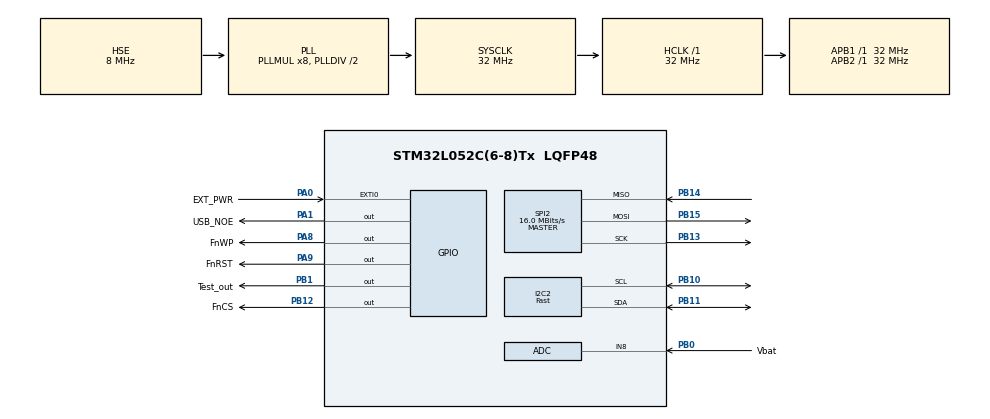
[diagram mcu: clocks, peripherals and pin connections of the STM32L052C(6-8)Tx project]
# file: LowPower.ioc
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I2C2.I2C_Speed_Mode=I2C_Fast
I2C2.Timing=0x00300F38
Mcu.Family=STM32L0
Mcu.Name=STM32L052C(6-8)Tx
Mcu.Package=LQFP48
NVIC.EXTI0_1_IRQn=true\:0\:0\:false\:false\:true\:true\:true\:true
NVIC.PVD_IRQn=true\:0\:0\:false\:false\:true\:true\:true\:true
NVIC.RCC_CRS_IRQn=true\:0\:0\:false\:false\:true\:true\:false\:true
NVIC.RTC_IRQn=true\:0\:0\:false\:false\:true\:true\:true\:true
PA0.GPIO_Label=EXT_PWR
PA0.Signal=GPXTI0
PA1.GPIO_Label=USB_NOE
PA1.GPIO_PuPd=GPIO_NOPULL
PA1.GPIO_Speed=GPIO_SPEED_FREQ_LOW
PA1.PinState=GPIO_PIN_SET
PA1.Signal=GPIO_Output
PA13.Mode=Serial_Wire
PA13.Signal=SYS_SWDIO
PA14.Mode=Serial_Wire
PA14.Signal=SYS_SWCLK
PA8.GPIO_Label=FnWP
PA8.PinState=GPIO_PIN_SET
PA8.Signal=GPIO_Output
PA9.GPIO_Label=FnRST
PA9.PinState=GPIO_PIN_SET
PA9.Signal=GPIO_Output
PB0.GPIO_Label=Vbat
PB0.Mode=IN8
PB0.Signal=ADC_IN8
PB1.GPIO_Label=Test_out
PB1.Signal=GPIO_Output
PB10.GPIO_Pu=GPIO_PULLUP
PB10.Mode=I2C
PB10.Signal=I2C2_SCL
PB11.GPIO_Pu=GPIO_PULLUP
PB11.Mode=I2C
PB11.Signal=I2C2_SDA
PB12.GPIO_Label=FnCS
PB12.PinState=GPIO_PIN_SET
PB12.Signal=GPIO_Output
PB13.Mode=Full_Duplex_Master
PB13.Signal=SPI2_SCK
PB14.Mode=Full_Duplex_Master
PB14.Signal=SPI2_MISO
PB15.Mode=Full_Duplex_Master
PB15.Signal=SPI2_MOSI
PC14-OSC32_IN.Mode=LSE-External-Oscillator
PC14-OSC32_IN.Signal=RCC_OSC32_IN
PC15-OSC32_OUT.Mode=LSE-External-Oscillator
PC15-OSC32_OUT.Signal=RCC_OSC32_OUT
PH0-OSC_IN.Mode=HSE-External-Oscillator
PH0-OSC_IN.Signal=RCC_OSC_IN
PH1-OSC_OUT.Mode=HSE-External-Oscillator
PH1-OSC_OUT.Signal=RCC_OSC_OUT
ProjectManager.HeapSize=0x500
ProjectManager.StackSize=0x400
ProjectManager.TargetToolchain=Makefile
RCC.AHBFreq_Value=32000000
RCC.APB1Freq_Value=32000000
RCC.APB1TimFreq_Value=32000000
RCC.APB2Freq_Value=32000000
RCC.APB2TimFreq_Value=32000000
RCC.HCLKFreq_Value=32000000
RCC.HSE_VALUE=8000000
RCC.HSI16_VALUE=16000000
RCC.HSI48MClockSelection=RCC_USBCLKSOURCE_HSI48
RCC.HSI48_VALUE=48000000
RCC.HSI_VALUE=16000000
RCC.MSIClockRange=RCC_MSIRANGE_4
RCC.MSI_VALUE=1048000
RCC.PLLMUL=RCC_PLLMUL_8
RCC.PLLSourceVirtual=RCC_PLLSOURCE_HSE
RCC.RTCClockSelection=RCC_RTCCLKSOURCE_LSE
RCC.RTCClockSelectionVirtual=RCC_RTCCLKSOURCE_LSE
RCC.SYSCLKFreq_VALUE=32000000
RCC.SYSCLKSource=RCC_SYSCLKSOURCE_PLLCLK
RCC.VCOOutputFreq_Value=64000000
RTC.Alarm-Alarm\ A=RTC_ALARM_A
SPI2.BaudRatePrescaler=SPI_BAUDRATEPRESCALER_2
SPI2.CalculateBaudRate=16.0 MBits/s
SPI2.Direction=SPI_DIRECTION_2LINES
SPI2.Mode=SPI_MODE_MASTER
SPI2.VirtualType=VM_MASTER
TIM6.AutoReloadPreload=TIM_AUTORELOAD_PRELOAD_ENABLE
TIM6.Prescaler=31
VP_RTC_VS_RTC_Activate.Mode=RTC_Enabled
VP_RTC_VS_RTC_Alarm_A_Intern.Mode=Alarm A
VP_RTC_VS_RTC_Calendar.Mode=RTC_Calendar
VP_RTC_VS_RTC_WakeUp_intern.Mode=WakeUp
VP_TIM6_VS_ClockSourceINT.Mode=Enable_Timer
board=custom

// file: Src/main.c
/* USER CODE BEGIN Header */
/**
  ******************************************************************************
  * @file           : main.c
  * @brief          : Main program body
  ******************************************************************************
  * @attention
  *
  * Copyright (c) 2022 STMicroelectronics.
  * All rights reserved.
  *
  * This software is licensed under terms that can be found in the LICENSE file
  * in the root directory of this software component.
  * If no LICENSE file comes with this software, it is provided AS-IS.
  *
  ******************************************************************************
  */
/* USER CODE END Header */
#include "main.h"
#include "adc.h"
#include "i2c.h"
#include "rtc.h"
#include "spi.h"
#include "tim.h"
#include "gpio.h"

/* USER CODE BEGIN Includes */
#include <stdio.h>
#include "app/application.h"
/* USER CODE END Includes */

void SystemClock_Config(void);

int main(void)
{

  /* MCU Configuration--------------------------------------------------------*/

  /* Reset of all peripherals, Initializes the Flash interface and the Systick. */
  HAL_Init();

  /* Configure the system clock */
  SystemClock_Config();

  /* Initialize all configured peripherals */
  MX_GPIO_Init();
  MX_RTC_Init();
  MX_SPI2_Init();
  MX_I2C2_Init();
  MX_ADC_Init();
  MX_TIM6_Init();
  /* USER CODE BEGIN 2 */
  tim6_init();

  application_run();
  /* USER CODE END 2 */

  /* Infinite loop */
  while (1)
  {

  }
}

void SystemClock_Config(void)
{
  RCC_OscInitTypeDef RCC_OscInitStruct = {0};
  RCC_ClkInitTypeDef RCC_ClkInitStruct = {0};
  RCC_PeriphCLKInitTypeDef PeriphClkInit = {0};

  /** Configure the main internal regulator output voltage
  */
  __HAL_PWR_VOLTAGESCALING_CONFIG(PWR_REGULATOR_VOLTAGE_SCALE1);

  /** Configure LSE Drive Capability
  */
  HAL_PWR_EnableBkUpAccess();
  __HAL_RCC_LSEDRIVE_CONFIG(RCC_LSEDRIVE_LOW);

  /** Initializes the RCC Oscillators according to the specified parameters
  * in the RCC_OscInitTypeDef structure.
  */
  RCC_OscInitStruct.OscillatorType = RCC_OSCILLATORTYPE_HSE|RCC_OSCILLATORTYPE_LSE;
  RCC_OscInitStruct.HSEState = RCC_HSE_ON;
  RCC_OscInitStruct.LSEState = RCC_LSE_ON;
  RCC_OscInitStruct.PLL.PLLState = RCC_PLL_ON;
  RCC_OscInitStruct.PLL.PLLSource = RCC_PLLSOURCE_HSE;
  RCC_OscInitStruct.PLL.PLLMUL = RCC_PLLMUL_8;
  RCC_OscInitStruct.PLL.PLLDIV = RCC_PLLDIV_2;
  if (HAL_RCC_OscConfig(&RCC_OscInitStruct) != HAL_OK)
  {
    Error_Handler();
  }

  /** Initializes the CPU, AHB and APB buses clocks
  */
  RCC_ClkInitStruct.ClockType = RCC_CLOCKTYPE_HCLK|RCC_CLOCKTYPE_SYSCLK
                              |RCC_CLOCKTYPE_PCLK1|RCC_CLOCKTYPE_PCLK2;
  RCC_ClkInitStruct.SYSCLKSource = RCC_SYSCLKSOURCE_PLLCLK;
  RCC_ClkInitStruct.AHBCLKDivider = RCC_SYSCLK_DIV1;
  RCC_ClkInitStruct.APB1CLKDivider = RCC_HCLK_DIV1;
  RCC_ClkInitStruct.APB2CLKDivider = RCC_HCLK_DIV1;

  if (HAL_RCC_ClockConfig(&RCC_ClkInitStruct, FLASH_LATENCY_1) != HAL_OK)
  {
    Error_Handler();
  }
  PeriphClkInit.PeriphClockSelection = RCC_PERIPHCLK_RTC;
  PeriphClkInit.RTCClockSelection = RCC_RTCCLKSOURCE_LSE;
  if (HAL_RCCEx_PeriphCLKConfig(&PeriphClkInit) != HAL_OK)
  {
    Error_Handler();
  }
}

void Error_Handler(void)
{
  __disable_irq();
  while (1)
  {
  }
}
